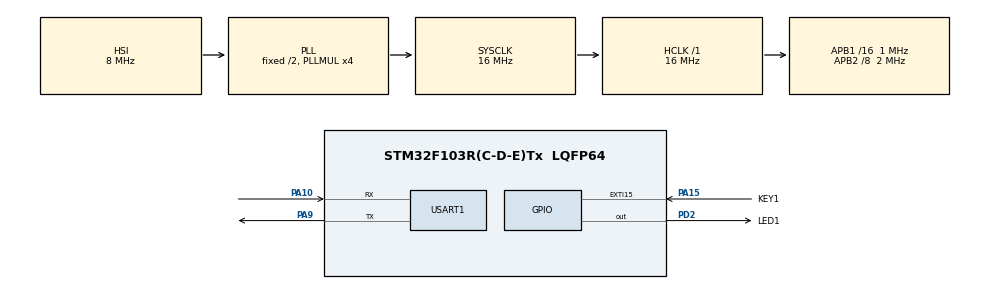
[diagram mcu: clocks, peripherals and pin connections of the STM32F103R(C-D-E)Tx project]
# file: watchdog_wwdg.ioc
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Mcu.Family=STM32F1
Mcu.Name=STM32F103R(C-D-E)Tx
Mcu.Package=LQFP64
NVIC.EXTI15_10_IRQn=true\:1\:2\:true\:false\:true\:true\:true\:true
NVIC.PriorityGroup=NVIC_PRIORITYGROUP_2
NVIC.TIM6_IRQn=true\:1\:1\:true\:false\:true\:true\:true\:true
NVIC.WWDG_IRQn=true\:1\:0\:true\:false\:true\:true\:true\:true
PA10.Mode=Asynchronous
PA10.Signal=USART1_RX
PA13.Mode=Serial_Wire
PA13.Signal=SYS_JTMS-SWDIO
PA14.Mode=Serial_Wire
PA14.Signal=SYS_JTCK-SWCLK
PA15.GPIO_Label=KEY1
PA15.GPIO_PuPd=GPIO_PULLUP
PA15.Signal=GPXTI15
PA9.Mode=Asynchronous
PA9.Signal=USART1_TX
PD0-OSC_IN.Mode=HSE-External-Oscillator
PD0-OSC_IN.Signal=RCC_OSC_IN
PD1-OSC_OUT.Mode=HSE-External-Oscillator
PD1-OSC_OUT.Signal=RCC_OSC_OUT
PD2.GPIO_Label=LED1
PD2.Signal=GPIO_Output
ProjectManager.HeapSize=0x200
ProjectManager.StackSize=0x400
ProjectManager.TargetToolchain=CMake
RCC.AHBFreq_Value=16000000
RCC.APB1CLKDivider=RCC_HCLK_DIV16
RCC.APB1Freq_Value=1000000
RCC.APB1TimFreq_Value=2000000
RCC.APB2CLKDivider=RCC_HCLK_DIV8
RCC.APB2Freq_Value=2000000
RCC.APB2TimFreq_Value=4000000
RCC.HCLKFreq_Value=16000000
RCC.PLLMUL=RCC_PLL_MUL4
RCC.SYSCLKFreq_VALUE=16000000
RCC.SYSCLKSource=RCC_SYSCLKSOURCE_PLLCLK
RCC.USBFreq_Value=16000000
TIM6.AutoReloadPreload=TIM_AUTORELOAD_PRELOAD_ENABLE
USART1.VirtualMode=VM_ASYNC
VP_TIM6_VS_ClockSourceINT.Mode=Enable_Timer
VP_WWDG_VS_WWDG.Mode=WWDG_Activate
WWDG.Counter=127
WWDG.EWIMode=WWDG_EWI_ENABLE
WWDG.Prescaler=WWDG_PRESCALER_8
WWDG.Window=95
board=custom

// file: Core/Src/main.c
/* USER CODE BEGIN Header */
/**
  ******************************************************************************
  * @file           : main.c
  * @brief          : Main program body
  ******************************************************************************
  * @attention
  *
  * Copyright (c) 2024 STMicroelectronics.
  * All rights reserved.
  *
  * This software is licensed under terms that can be found in the LICENSE file
  * in the root directory of this software component.
  * If no LICENSE file comes with this software, it is provided AS-IS.
  *
  ******************************************************************************
  */
/* USER CODE END Header */
#include "main.h"

#include <stdio.h>
#include <string.h>

#include "gpio.h"
#include "stm32f103xe.h"
#include "stm32f1xx_hal.h"
#include "stm32f1xx_hal_gpio.h"
#include "stm32f1xx_hal_uart.h"
#include "tim.h"
#include "usart.h"
#include "wwdg.h"

void SystemClock_Config(void);

int main(void)
{

  /* MCU Configuration--------------------------------------------------------*/

  /* Reset of all peripherals, Initializes the Flash interface and the Systick. */
  HAL_Init();

  /* Configure the system clock */
  SystemClock_Config();

  /* Initialize all configured peripherals */
  MX_GPIO_Init();
  MX_USART1_UART_Init();
  MX_WWDG_Init();
  MX_TIM6_Init();

  /* Infinite loop */
  /* USER CODE BEGIN WHILE */
  HAL_GPIO_WritePin(GPIOD, LED1_Pin, GPIO_PIN_SET);
  int i = 0;
  unsigned char msg[100];
  sprintf(msg, "Restarting...\r\n");
  HAL_UART_Transmit(&huart1, msg, 16, HAL_MAX_DELAY);
  while (1)
  {
    /* USER CODE END WHILE */

    /* USER CODE BEGIN 3 */
    i++;
    sprintf(msg, "i = %d\r\n", i);
    HAL_UART_Transmit(&huart1, msg, strlen(msg), HAL_MAX_DELAY);
    HAL_Delay(1000);
  }
  /* USER CODE END 3 */
}

void SystemClock_Config(void)
{
  RCC_OscInitTypeDef RCC_OscInitStruct = {0};
  RCC_ClkInitTypeDef RCC_ClkInitStruct = {0};

  /** Initializes the RCC Oscillators according to the specified parameters
  * in the RCC_OscInitTypeDef structure.
  */
  RCC_OscInitStruct.OscillatorType = RCC_OSCILLATORTYPE_HSI;
  RCC_OscInitStruct.HSIState = RCC_HSI_ON;
  RCC_OscInitStruct.HSICalibrationValue = RCC_HSICALIBRATION_DEFAULT;
  RCC_OscInitStruct.PLL.PLLState = RCC_PLL_ON;
  RCC_OscInitStruct.PLL.PLLSource = RCC_PLLSOURCE_HSI_DIV2;
  RCC_OscInitStruct.PLL.PLLMUL = RCC_PLL_MUL4;
  if (HAL_RCC_OscConfig(&RCC_OscInitStruct) != HAL_OK)
  {
    Error_Handler();
  }

  /** Initializes the CPU, AHB and APB buses clocks
  */
  RCC_ClkInitStruct.ClockType = RCC_CLOCKTYPE_HCLK|RCC_CLOCKTYPE_SYSCLK
                              |RCC_CLOCKTYPE_PCLK1|RCC_CLOCKTYPE_PCLK2;
  RCC_ClkInitStruct.SYSCLKSource = RCC_SYSCLKSOURCE_PLLCLK;
  RCC_ClkInitStruct.AHBCLKDivider = RCC_SYSCLK_DIV1;
  RCC_ClkInitStruct.APB1CLKDivider = RCC_HCLK_DIV16;
  RCC_ClkInitStruct.APB2CLKDivider = RCC_HCLK_DIV8;

  if (HAL_RCC_ClockConfig(&RCC_ClkInitStruct, FLASH_LATENCY_0) != HAL_OK)
  {
    Error_Handler();
  }
}

void Error_Handler(void)
{
  __disable_irq();
  while (1)
  {
  }
}
